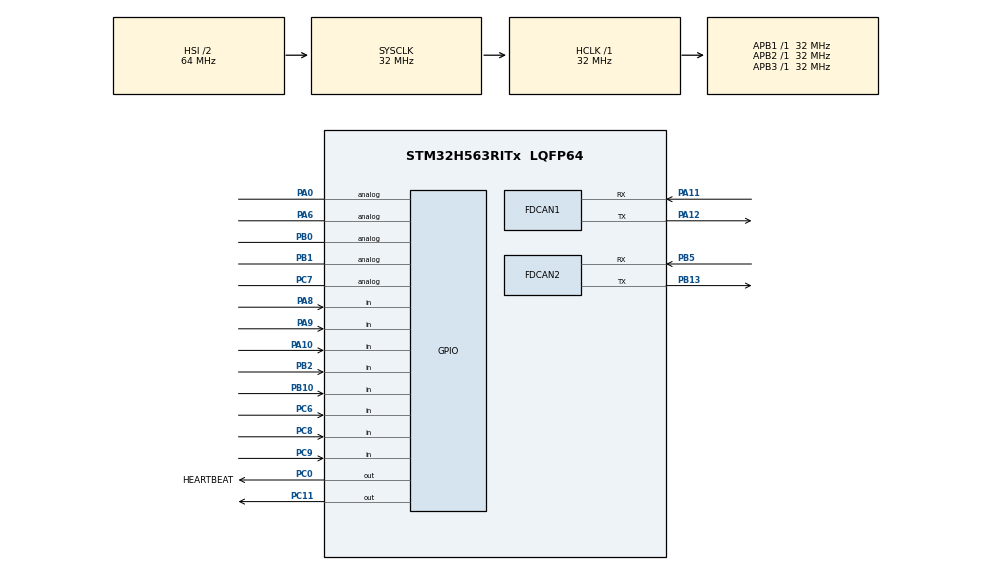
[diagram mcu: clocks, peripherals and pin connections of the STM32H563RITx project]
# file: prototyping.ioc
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BOOTPATH.BootPathName=LEGACY
BOOTPATH.UserSelectedBootPath=LEGACY
CORTEX_M33_NS.Number-Cortex_Memory_Protection_Unit_Region0_OTP_RO_AREAS_Settings=MPU_REGION_NUMBER0
CORTEX_M33_NS.default_mode_Activation=1
CORTEX_M33_NS.userName=CORTEX_M33
FDCAN1.CalculateBaudRateNominal=125000
FDCAN1.CalculateTimeBitNominal=8000
FDCAN1.CalculateTimeQuantumNominal=500.0
FDCAN1.NominalTimeSeg1=8
FDCAN1.NominalTimeSeg2=7
FDCAN2.CalculateBaudRateNominal=666666
FDCAN2.CalculateTimeBitNominal=1500
FDCAN2.CalculateTimeQuantumNominal=500.0
Mcu.Family=STM32H5
Mcu.Name=STM32H563RITx
Mcu.Package=LQFP64
NVIC.FDCAN1_IT0_IRQn=true\:0\:0\:false\:false\:true\:true\:true\:true
NVIC.PriorityGroup=NVIC_PRIORITYGROUP_4
PA0.Signal=GPIO_Analog
PA10.Signal=GPIO_Input
PA11.Mode=FDCAN_Activate
PA11.Signal=FDCAN1_RX
PA12.Mode=FDCAN_Activate
PA12.Signal=FDCAN1_TX
PA13(JTMS/SWDIO).Mode=Trace_Asynchronous_SW
PA13(JTMS/SWDIO).Signal=DEBUG_JTMS-SWDIO
PA14(JTCK/SWCLK).Mode=Trace_Asynchronous_SW
PA14(JTCK/SWCLK).Signal=DEBUG_JTCK-SWCLK
PA6.Signal=GPIO_Analog
PA8.Signal=GPIO_Input
PA9.Signal=GPIO_Input
PB0.Signal=GPIO_Analog
PB1.Signal=GPIO_Analog
PB10.Signal=GPIO_Input
PB13.Mode=FDCAN_Activate
PB13.Signal=FDCAN2_TX
PB2.Signal=GPIO_Input
PB3(JTDO/TRACESWO).Mode=Trace_Asynchronous_SW
PB3(JTDO/TRACESWO).Signal=DEBUG_JTDO-SWO
PB5.Mode=FDCAN_Activate
PB5.Signal=FDCAN2_RX
PC0.GPIO_Label=HEARTBEAT
PC0.Signal=GPIO_Output
PC11.Signal=GPIO_Output
PC6.Signal=GPIO_Input
PC7.Signal=GPIO_Analog
PC8.Signal=GPIO_Input
PC9.Signal=GPIO_Input
ProjectManager.HeapSize=0x200
ProjectManager.StackSize=0x400
ProjectManager.TargetToolchain=STM32CubeIDE
RCC.ADCFreq_Value=32000000
RCC.AHBFreq_Value=32000000
RCC.APB1Freq_Value=32000000
RCC.APB1TimFreq_Value=32000000
RCC.APB2Freq_Value=32000000
RCC.APB2TimFreq_Value=32000000
RCC.APB3Freq_Value=32000000
RCC.CSI_VALUE=4000000
RCC.CortexFreq_Value=32000000
RCC.EPOD_VALUE=4000000
RCC.FDCANClockSelection=RCC_FDCANCLKSOURCE_PLL2Q
RCC.HCLKFreq_Value=32000000
RCC.HSE_VALUE=25000000
RCC.HSI48_VALUE=48000000
RCC.HSI_VALUE=64000000
RCC.LSE_VALUE=32768
RCC.LSIRC_VALUE=32000
RCC.PLL1Q=6
RCC.PLL2FRACN=0
RCC.PLL2N=32
RCC.PLL2Q=4
RCC.SYSCLKFreq_VALUE=32000000
RCC.USBFreq_Value=48000000
RCC.VCOOutputFreq_Value=516000000
VP_BOOTPATH_VS_BOOTPATH.Mode=BP_Activate
VP_CORTEX_M33_NS_VS_Hclk.Mode=Hclk_Mode
VP_ICACHE_VS_ICACHE.Mode=DirectMappedCache
VP_MEMORYMAP_VS_MEMORYMAP.Mode=CurAppReg
VP_PWR_VS_LPOM.Mode=PowerOptimisation
VP_PWR_VS_SECSignals.Mode=Security/Privilege
board=custom

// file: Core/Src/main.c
/* USER CODE BEGIN Header */
/**
  ******************************************************************************
  * @file           : main.c
  * @brief          : Main program body
  ******************************************************************************
  * @attention
  *
  * Copyright (c) 2026 STMicroelectronics.
  * All rights reserved.
  *
  * This software is licensed under terms that can be found in the LICENSE file
  * in the root directory of this software component.
  * If no LICENSE file comes with this software, it is provided AS-IS.
  *
  ******************************************************************************
  */
/* USER CODE END Header */
#include "main.h"

/* USER CODE BEGIN Includes */
#include <stdio.h>
#include <stdlib.h>
/* USER CODE END Includes */

FDCAN_HandleTypeDef hfdcan1;
FDCAN_HandleTypeDef hfdcan2;

void SystemClock_Config(void);
void PeriphCommonClock_Config(void);
static void MPU_Config(void);
static void MX_GPIO_Init(void);
static void MX_FDCAN1_Init(void);
static void MX_ICACHE_Init(void);
static void MX_FDCAN2_Init(void);

int main(void)
{

  /* MCU Configuration--------------------------------------------------------*/

  /* MPU Configuration--------------------------------------------------------*/
  MPU_Config();

  /* Reset of all peripherals, Initializes the Flash interface and the Systick. */
  HAL_Init();

  /* Configure the system clock */
  SystemClock_Config();

  /* Configure the peripherals common clocks */
  PeriphCommonClock_Config();

  /* Initialize all configured peripherals */
  MX_GPIO_Init();
  MX_FDCAN1_Init();
  MX_ICACHE_Init();
  MX_FDCAN2_Init();

  /* Infinite loop */
  while (1)
  {
	  if (1 == 1) //(HAL_GPIO_ReadPin(GPIOB,GPIO_PIN_2) == 1)if in joint mode
	  {
		  if (HAL_GPIO_ReadPin(GPIOC,GPIO_PIN_6) == 0)//if button 1 pressed
		  {
			  HAL_GPIO_WritePin(GPIOC,GPIO_PIN_0,1);
			  //move moto
		  }
		  else
		  {
			  HAL_GPIO_WritePin(GPIOC,GPIO_PIN_0,0);
			  // no move motor
		  }
		  if (HAL_GPIO_ReadPin(GPIOC,GPIO_PIN_8) == 0)//if button 2 pressed
		  		  {
		  			  HAL_GPIO_WritePin(GPIOC,GPIO_PIN_0,1);
		  			  //move moto
		  		  }
		  		  else
		  		  {
		  			  HAL_GPIO_WritePin(GPIOC,GPIO_PIN_0,0);
		  			  // no move motor
		  		  }
		  if (HAL_GPIO_ReadPin(GPIOC,GPIO_PIN_9) == 0)//if button 3 pressed
		  		  {
		  			  HAL_GPIO_WritePin(GPIOC,GPIO_PIN_0,1);
		  			  //move moto
		  		  }
		  		  else
		  		  {
		  			  HAL_GPIO_WritePin(GPIOC,GPIO_PIN_0,0);
		  			  // no move motor
		  		  }
		  if (HAL_GPIO_ReadPin(GPIOA,GPIO_PIN_8) == 0)//if button 4 pressed
		  		  {
		  			  HAL_GPIO_WritePin(GPIOC,GPIO_PIN_0,1);
		  			  //move moto
		  		  }
		  		  else
		  		  {
		  			  HAL_GPIO_WritePin(GPIOC,GPIO_PIN_0,0);
		  			  // no move motor
		  		  }
		  if (HAL_GPIO_ReadPin(GPIOA,GPIO_PIN_9) == 0)//if button 5 pressed
		  		  {
		  			  HAL_GPIO_WritePin(GPIOC,GPIO_PIN_0,1);
		  			  //move moto
		  		  }
		  		  else
		  		  {
		  			  HAL_GPIO_WritePin(GPIOC,GPIO_PIN_0,0);
		  			  // no move motor
		  		  }
		  if (HAL_GPIO_ReadPin(GPIOA,GPIO_PIN_10) == 0)//if button 1 pressed
		  		  {
		  			  HAL_GPIO_WritePin(GPIOC,GPIO_PIN_0,1);
		  			  //move moto
		  		  }
		  		  else
		  		  {
		  			  HAL_GPIO_WritePin(GPIOC,GPIO_PIN_0,0);
		  			  // no move motor
		  		  }
	  }
	  else// in servo mode
	  {
		  if (HAL_GPIO_ReadPin(GPIOC,GPIO_PIN_6) == 0)//if button 1 pressed
		 		  {
		 			  HAL_GPIO_WritePin(GPIOC,GPIO_PIN_0,1);
		 			  //move moto
		 		  }
		 		  else
		 		  {
		 			  HAL_GPIO_WritePin(GPIOC,GPIO_PIN_0,0);
		 			  // no move motor
		 		  }
		 		  if (HAL_GPIO_ReadPin(GPIOC,GPIO_PIN_8) == 0)//if button 2 pressed
		 		  		  {
		 		  			  HAL_GPIO_WritePin(GPIOC,GPIO_PIN_0,1);
		 		  			  //move moto
		 		  		  }
		 		  		  else
		 		  		  {
		 		  			  HAL_GPIO_WritePin(GPIOC,GPIO_PIN_0,0);
		 		  			  // no move motor
		 		  		  }
		 		  if (HAL_GPIO_ReadPin(GPIOC,GPIO_PIN_9) == 0)//if button 3 pressed
		 		  		  {
		 		  			  HAL_GPIO_WritePin(GPIOC,GPIO_PIN_0,1);
		 		  			  //move moto
		 		  		  }
		 		  		  else
		 		  		  {
		 		  			  HAL_GPIO_WritePin(GPIOC,GPIO_PIN_0,0);
		 		  			  // no move motor
		 		  		  }
		 		  if (HAL_GPIO_ReadPin(GPIOA,GPIO_PIN_8) == 0)//if button 4 pressed
		 		  		  {
		 		  			  HAL_GPIO_WritePin(GPIOC,GPIO_PIN_0,1);
		 		  			  //move moto
		 		  		  }
		 		  		  else
		 		  		  {
		 		  			  HAL_GPIO_WritePin(GPIOC,GPIO_PIN_0,0);
		 		  			  // no move motor
		 		  		  }
		 		  if (HAL_GPIO_ReadPin(GPIOA,GPIO_PIN_9) == 0)//if button 5 pressed
		 		  		  {
		 		  			  HAL_GPIO_WritePin(GPIOC,GPIO_PIN_0,1);
		 		  			  //move moto
		 		  		  }
		 		  		  else
		 		  		  {
		 		  			  HAL_GPIO_WritePin(GPIOC,GPIO_PIN_0,0);
		 		  			  // no move motor
		 		  		  }
		 		  if (HAL_GPIO_ReadPin(GPIOA,GPIO_PIN_10) == 0)//if button 1 pressed
		 		  		  {
		 		  			  HAL_GPIO_WritePin(GPIOC,GPIO_PIN_0,1);
		 		  			  //move moto
		 		  		  }
		 		  		  else
		 		  		  {
		 		  			  HAL_GPIO_WritePin(GPIOC,GPIO_PIN_0,0);
		 		  			  // no move motor
		 		  		  }
	  }
  }
}

void SystemClock_Config(void)
{
  RCC_OscInitTypeDef RCC_OscInitStruct = {0};
  RCC_ClkInitTypeDef RCC_ClkInitStruct = {0};

  /** Configure the main internal regulator output voltage
  */
  __HAL_PWR_VOLTAGESCALING_CONFIG(PWR_REGULATOR_VOLTAGE_SCALE3);

  while(!__HAL_PWR_GET_FLAG(PWR_FLAG_VOSRDY)) {}

  /** Initializes the RCC Oscillators according to the specified parameters
  * in the RCC_OscInitTypeDef structure.
  */
  RCC_OscInitStruct.OscillatorType = RCC_OSCILLATORTYPE_HSI|RCC_OSCILLATORTYPE_CSI;
  RCC_OscInitStruct.HSIState = RCC_HSI_ON;
  RCC_OscInitStruct.HSIDiv = RCC_HSI_DIV2;
  RCC_OscInitStruct.HSICalibrationValue = RCC_HSICALIBRATION_DEFAULT;
  RCC_OscInitStruct.CSIState = RCC_CSI_ON;
  RCC_OscInitStruct.CSICalibrationValue = RCC_CSICALIBRATION_DEFAULT;
  RCC_OscInitStruct.PLL.PLLState = RCC_PLL_NONE;
  if (HAL_RCC_OscConfig(&RCC_OscInitStruct) != HAL_OK)
  {
    Error_Handler();
  }

  /** Initializes the CPU, AHB and APB buses clocks
  */
  RCC_ClkInitStruct.ClockType = RCC_CLOCKTYPE_HCLK|RCC_CLOCKTYPE_SYSCLK
                              |RCC_CLOCKTYPE_PCLK1|RCC_CLOCKTYPE_PCLK2
                              |RCC_CLOCKTYPE_PCLK3;
  RCC_ClkInitStruct.SYSCLKSource = RCC_SYSCLKSOURCE_HSI;
  RCC_ClkInitStruct.AHBCLKDivider = RCC_SYSCLK_DIV1;
  RCC_ClkInitStruct.APB1CLKDivider = RCC_HCLK_DIV1;
  RCC_ClkInitStruct.APB2CLKDivider = RCC_HCLK_DIV1;
  RCC_ClkInitStruct.APB3CLKDivider = RCC_HCLK_DIV1;

  if (HAL_RCC_ClockConfig(&RCC_ClkInitStruct, FLASH_LATENCY_1) != HAL_OK)
  {
    Error_Handler();
  }

  /** Configure the programming delay
  */
  __HAL_FLASH_SET_PROGRAM_DELAY(FLASH_PROGRAMMING_DELAY_0);
}

void PeriphCommonClock_Config(void)
{
  RCC_PeriphCLKInitTypeDef PeriphClkInitStruct = {0};

  /** Initializes the peripherals clock
  */
  PeriphClkInitStruct.PeriphClockSelection = RCC_PERIPHCLK_FDCAN;
  PeriphClkInitStruct.PLL2.PLL2Source = RCC_PLL2_SOURCE_CSI;
  PeriphClkInitStruct.PLL2.PLL2M = 1;
  PeriphClkInitStruct.PLL2.PLL2N = 32;
  PeriphClkInitStruct.PLL2.PLL2P = 2;
  PeriphClkInitStruct.PLL2.PLL2Q = 4;
  PeriphClkInitStruct.PLL2.PLL2R = 2;
  PeriphClkInitStruct.PLL2.PLL2RGE = RCC_PLL2_VCIRANGE_2;
  PeriphClkInitStruct.PLL2.PLL2VCOSEL = RCC_PLL2_VCORANGE_WIDE;
  PeriphClkInitStruct.PLL2.PLL2FRACN = 0;
  PeriphClkInitStruct.PLL2.PLL2ClockOut = RCC_PLL2_DIVQ;
  PeriphClkInitStruct.FdcanClockSelection = RCC_FDCANCLKSOURCE_PLL2Q;
  if (HAL_RCCEx_PeriphCLKConfig(&PeriphClkInitStruct) != HAL_OK)
  {
    Error_Handler();
  }
}

static void MX_FDCAN1_Init(void)
{

  hfdcan1.Instance = FDCAN1;
  hfdcan1.Init.ClockDivider = FDCAN_CLOCK_DIV1;
  hfdcan1.Init.FrameFormat = FDCAN_FRAME_CLASSIC;
  hfdcan1.Init.Mode = FDCAN_MODE_NORMAL;
  hfdcan1.Init.AutoRetransmission = DISABLE;
  hfdcan1.Init.TransmitPause = DISABLE;
  hfdcan1.Init.ProtocolException = DISABLE;
  hfdcan1.Init.NominalPrescaler = 16;
  hfdcan1.Init.NominalSyncJumpWidth = 1;
  hfdcan1.Init.NominalTimeSeg1 = 8;
  hfdcan1.Init.NominalTimeSeg2 = 7;
  hfdcan1.Init.DataPrescaler = 1;
  hfdcan1.Init.DataSyncJumpWidth = 1;
  hfdcan1.Init.DataTimeSeg1 = 1;
  hfdcan1.Init.DataTimeSeg2 = 1;
  hfdcan1.Init.StdFiltersNbr = 0;
  hfdcan1.Init.ExtFiltersNbr = 0;
  hfdcan1.Init.TxFifoQueueMode = FDCAN_TX_FIFO_OPERATION;
  if (HAL_FDCAN_Init(&hfdcan1) != HAL_OK)
  {
    Error_Handler();
  }

}

static void MX_FDCAN2_Init(void)
{

  hfdcan2.Instance = FDCAN2;
  hfdcan2.Init.ClockDivider = FDCAN_CLOCK_DIV1;
  hfdcan2.Init.FrameFormat = FDCAN_FRAME_CLASSIC;
  hfdcan2.Init.Mode = FDCAN_MODE_NORMAL;
  hfdcan2.Init.AutoRetransmission = DISABLE;
  hfdcan2.Init.TransmitPause = DISABLE;
  hfdcan2.Init.ProtocolException = DISABLE;
  hfdcan2.Init.NominalPrescaler = 16;
  hfdcan2.Init.NominalSyncJumpWidth = 1;
  hfdcan2.Init.NominalTimeSeg1 = 1;
  hfdcan2.Init.NominalTimeSeg2 = 1;
  hfdcan2.Init.DataPrescaler = 1;
  hfdcan2.Init.DataSyncJumpWidth = 1;
  hfdcan2.Init.DataTimeSeg1 = 1;
  hfdcan2.Init.DataTimeSeg2 = 1;
  hfdcan2.Init.StdFiltersNbr = 0;
  hfdcan2.Init.ExtFiltersNbr = 0;
  hfdcan2.Init.TxFifoQueueMode = FDCAN_TX_FIFO_OPERATION;
  if (HAL_FDCAN_Init(&hfdcan2) != HAL_OK)
  {
    Error_Handler();
  }

}

static void MX_ICACHE_Init(void)
{

  /** Enable instruction cache in 1-way (direct mapped cache)
  */
  if (HAL_ICACHE_ConfigAssociativityMode(ICACHE_1WAY) != HAL_OK)
  {
    Error_Handler();
  }
  if (HAL_ICACHE_Enable() != HAL_OK)
  {
    Error_Handler();
  }

}

static void MX_GPIO_Init(void)
{
  GPIO_InitTypeDef GPIO_InitStruct = {0};

  /* GPIO Ports Clock Enable */
  __HAL_RCC_GPIOC_CLK_ENABLE();
  __HAL_RCC_GPIOA_CLK_ENABLE();
  __HAL_RCC_GPIOB_CLK_ENABLE();

  /*Configure GPIO pin Output Level */
  HAL_GPIO_WritePin(GPIOC, HEARTBEAT_Pin|GPIO_PIN_11, GPIO_PIN_RESET);

  /*Configure GPIO pins : HEARTBEAT_Pin PC11 */
  GPIO_InitStruct.Pin = HEARTBEAT_Pin|GPIO_PIN_11;
  GPIO_InitStruct.Mode = GPIO_MODE_OUTPUT_PP;
  GPIO_InitStruct.Pull = GPIO_NOPULL;
  GPIO_InitStruct.Speed = GPIO_SPEED_FREQ_LOW;
  HAL_GPIO_Init(GPIOC, &GPIO_InitStruct);

  /*Configure GPIO pins : PA0 PA6 */
  GPIO_InitStruct.Pin = GPIO_PIN_0|GPIO_PIN_6;
  GPIO_InitStruct.Mode = GPIO_MODE_ANALOG;
  GPIO_InitStruct.Pull = GPIO_NOPULL;
  HAL_GPIO_Init(GPIOA, &GPIO_InitStruct);

  /*Configure GPIO pins : PB0 PB1 */
  GPIO_InitStruct.Pin = GPIO_PIN_0|GPIO_PIN_1;
  GPIO_InitStruct.Mode = GPIO_MODE_ANALOG;
  GPIO_InitStruct.Pull = GPIO_NOPULL;
  HAL_GPIO_Init(GPIOB, &GPIO_InitStruct);

  /*Configure GPIO pins : PB2 PB10 */
  GPIO_InitStruct.Pin = GPIO_PIN_2|GPIO_PIN_10;
  GPIO_InitStruct.Mode = GPIO_MODE_INPUT;
  GPIO_InitStruct.Pull = GPIO_NOPULL;
  HAL_GPIO_Init(GPIOB, &GPIO_InitStruct);

  /*Configure GPIO pins : PC6 PC8 PC9 */
  GPIO_InitStruct.Pin = GPIO_PIN_6|GPIO_PIN_8|GPIO_PIN_9;
  GPIO_InitStruct.Mode = GPIO_MODE_INPUT;
  GPIO_InitStruct.Pull = GPIO_NOPULL;
  HAL_GPIO_Init(GPIOC, &GPIO_InitStruct);

  /*Configure GPIO pin : PC7 */
  GPIO_InitStruct.Pin = GPIO_PIN_7;
  GPIO_InitStruct.Mode = GPIO_MODE_ANALOG;
  GPIO_InitStruct.Pull = GPIO_NOPULL;
  HAL_GPIO_Init(GPIOC, &GPIO_InitStruct);

  /*Configure GPIO pins : PA8 PA9 PA10 */
  GPIO_InitStruct.Pin = GPIO_PIN_8|GPIO_PIN_9|GPIO_PIN_10;
  GPIO_InitStruct.Mode = GPIO_MODE_INPUT;
  GPIO_InitStruct.Pull = GPIO_NOPULL;
  HAL_GPIO_Init(GPIOA, &GPIO_InitStruct);

}

 /* MPU Configuration */

void MPU_Config(void)
{
  MPU_Region_InitTypeDef MPU_InitStruct = {0};
  MPU_Attributes_InitTypeDef MPU_AttributesInit = {0};

  /* Disables the MPU */
  HAL_MPU_Disable();

  /** Initializes and configures the Region 0 and the memory to be protected
  */
  MPU_InitStruct.Enable = MPU_REGION_ENABLE;
  MPU_InitStruct.Number = MPU_REGION_NUMBER0;
  MPU_InitStruct.BaseAddress = 0x08FFF000;
  MPU_InitStruct.LimitAddress = 0x08FFFFFF;
  MPU_InitStruct.AttributesIndex = MPU_ATTRIBUTES_NUMBER0;
  MPU_InitStruct.AccessPermission = MPU_REGION_ALL_RO;
  MPU_InitStruct.DisableExec = MPU_INSTRUCTION_ACCESS_DISABLE;
  MPU_InitStruct.IsShareable = MPU_ACCESS_NOT_SHAREABLE;

  HAL_MPU_ConfigRegion(&MPU_InitStruct);

  /** Initializes and configures the Attribute 0 and the memory to be protected
  */
  MPU_AttributesInit.Number = MPU_ATTRIBUTES_NUMBER0;
  MPU_AttributesInit.Attributes = INNER_OUTER(MPU_NOT_CACHEABLE);

  HAL_MPU_ConfigMemoryAttributes(&MPU_AttributesInit);
  /* Enables the MPU */
  HAL_MPU_Enable(MPU_PRIVILEGED_DEFAULT);

}

void Error_Handler(void)
{
  __disable_irq();
  while (1)
  {
  }
}
